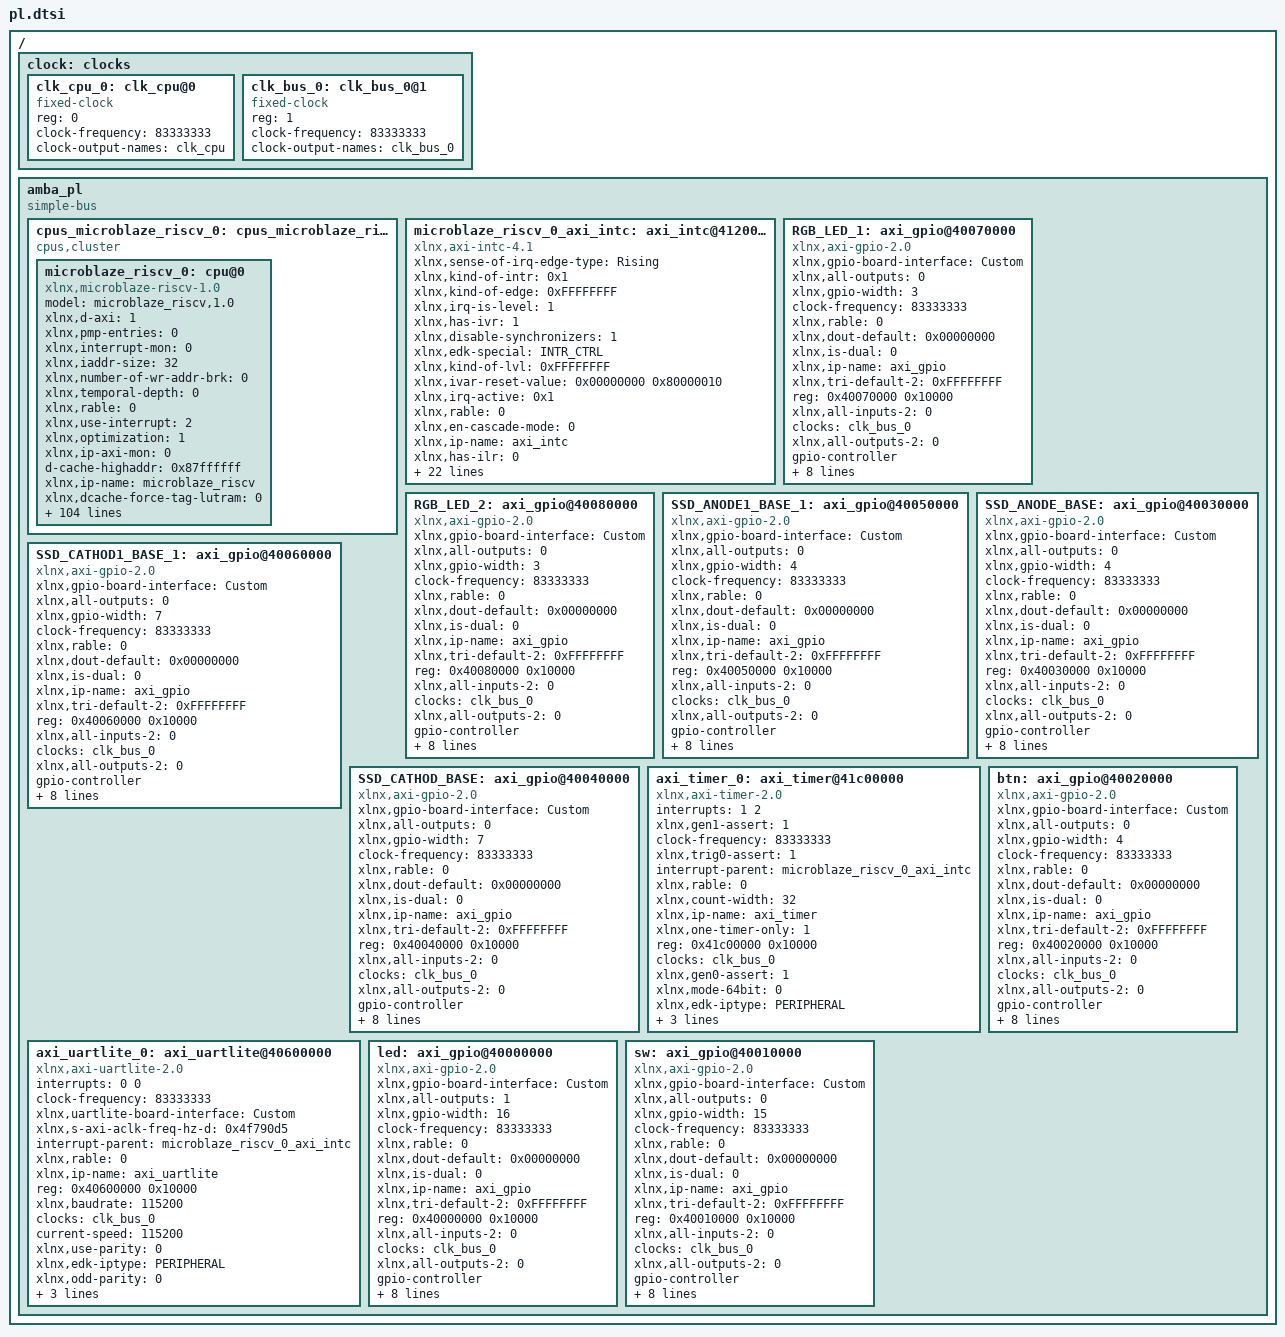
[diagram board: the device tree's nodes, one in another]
/ {
	clock: clocks {
		#address-cells = <1>;
		#size-cells = <0>;
		clk_cpu_0: clk_cpu@0 {
			compatible = "fixed-clock";
			reg = <0>;
			clock-frequency = <83333333>;
			clock-output-names = "clk_cpu";
			#clock-cells = <0>;
		};
		clk_bus_0: clk_bus_0@1 {
			compatible = "fixed-clock";
			reg = <1>;
			clock-frequency = <83333333>;
			clock-output-names = "clk_bus_0";
			#clock-cells = <0>;
		};
	};
	amba_pl: amba_pl {
		ranges;
		compatible = "simple-bus";
		#address-cells = <1>;
		#size-cells = <1>;
		cpus_microblaze_riscv_0: cpus_microblaze_riscv@0 {
			#cpu-mask-cells = <1>;
			compatible = "cpus,cluster";
			#address-cells = <1>;
			#size-cells = <0>;
			microblaze_riscv_0: cpu@0 {
				model = "microblaze_riscv,1.0";
				xlnx,d-axi = <1>;
				xlnx,pmp-entries = <0>;
				xlnx,interrupt-mon = <0>;
				xlnx,iaddr-size = <32>;
				xlnx,number-of-wr-addr-brk = <0>;
				xlnx,temporal-depth = <0>;
				xlnx,rable = <0>;
				xlnx,use-interrupt = <2>;
				xlnx,optimization = <1>;
				xlnx,ip-axi-mon = <0>;
				d-cache-highaddr = <0x87ffffff>;
				xlnx,ip-name = "microblaze_riscv";
				xlnx,dcache-force-tag-lutram = <0>;
				xlnx,pc-width = <27>;
				xlnx,interrupt-is-edge = <0>;
				reg = <0x0>;
				xlnx,async-interrupt = <1>;
				xlnx,use-mmu = <0>;
				xlnx,icache-victims = <0>;
				xlnx,use-bitman-a = <0>;
				xlnx,d-lmb-mon = <0>;
				xlnx,d-lmb-protocol = <0>;
				xlnx,use-bitman-b = <0>;
				xlnx,use-bitman-c = <0>;
				xlnx,dc-axi-mon = <0>;
				xlnx,debug-trace-async-reset = <0>;
				xlnx,trace = <0>;
				xlnx,part = "xc7s50csga324-1";
				xlnx,use-config-reset = <0>;
				xlnx,i-lmb-mon = <0>;
				xlnx,dcache-byte-size = <4096>;
				xlnx,ill-instr-exception = <1>;
				compatible = "xlnx,microblaze-riscv-1.0" , "xlnx,microblaze_riscv";
				xlnx,data-size = <32>;
				xlnx,fault-tolerant = <0>;
				xlnx,use-sleep = <0>;
				xlnx,debug-trace-size = <8192>;
				xlnx,pmp-granularity = <2>;
				xlnx,mmu-privileged-instr = <0>;
				d-cache-line-size = <16>;
				xlnx,d-lmb = <0>;
				xlnx,enable-discrete-ports = <0>;
				clock-frequency = <83333333>;
				xlnx,debug-interface = <0>;
				xlnx,use-ext-brk = <0>;
				xlnx,daddr-size = <32>;
				xlnx,debug-enabled = <1>;
				xlnx,num-sync-ff-dbg-trace-clk = <2>;
				xlnx,i-lmb-protocol = <0>;
				xlnx,fsl-exception = <0>;
				xlnx,use-extended-fsl-instr = <0>;
				xlnx,dp-axi-mon = <0>;
				xlnx,impid = <0x00000000 0x00000001>;
				xlnx,branch-target-cache-size = <0>;
				xlnx,dcache-use-writeback = <0>;
				xlnx,use-bitman-s = <0>;
				bus-handle = <&amba_pl>;
				xlnx,icache-line-len = <4>;
				xlnx,base-vectors = <0x00000000 0x80000000>;
				xlnx,ecc-use-ce-exception = <0>;
				xlnx,use-dcache = <1>;
				xlnx,use-barrel = <1>;
				xlnx,edk-special = "microblaze_riscv";
				xlnx,use-muldiv = <2>;
				xlnx,addr-size = <32>;
				xlnx,debug-external-trace = <0>;
				xlnx,piaddr-size = <32>;
				xlnx,misaligned-exceptions = <1>;
				xlnx,use-bitman = <0>;
				xlnx,num-sync-ff-clk-debug = <2>;
				xlnx,debug-event-counters = <0>;
				xlnx,use-atomic = <0>;
				xlnx,i-axi = <1>;
				xlnx,icache-streams = <0>;
				xlnx,g-template-list = <1>;
				xlnx,dcache-line-len = <4>;
				xlnx,num-sync-ff-clk = <2>;
				xlnx,num-sync-ff-dbg-clk = <1>;
				xlnx,interconnect = <2>;
				xlnx,hartid = <0x00000000 0x00000000>;
				xlnx,debug-latency-counters = <0>;
				xlnx,edk-iptype = "PROCESSOR";
				xlnx,use-fpu = <0>;
				xlnx,icache-byte-size = <8192>;
				xlnx,edge-is-positive = <1>;
				xlnx,use-icache = <0>;
				d-cache-size = <4096>;
				xlnx,async-wakeup = <3>;
				xlnx,use-non-secure = <0>;
				xlnx,number-of-rd-addr-brk = <0>;
				d-cache-baseaddr = <0x80000000>;
				xlnx,use-compression = <1>;
				xlnx,avoid-primitives = <0>;
				xlnx,use-counters = <1>;
				xlnx,lockstep-slave = <0>;
				xlnx,use-ext-nm-brk = <0>;
				xlnx,pdaddr-size = <32>;
				xlnx,instr-size = <32>;
				interrupt-handle = <&microblaze_riscv_0_axi_intc>;
				xlnx,i-lmb = <0>;
				xlnx,lockstep-select = <0>;
				xlnx,lmb-data-size = <32>;
				xlnx,ic-axi-mon = <0>;
				xlnx,num-sync-ff-clk-irq = <1>;
				xlnx,fsl-links = <0>;
				timebase-frequency = <83333333>;
				xlnx,archid = <0x00000000 0x00000001>;
				xlnx,icache-force-tag-lutram = <0>;
				xlnx,dcache-data-width = <0>;
				xlnx,dcache-victims = <0>;
				xlnx,use-branch-target-cache = <0>;
				xlnx,debug-profile-size = <0>;
				xlnx,lockstep-master = <0>;
				xlnx,freq = <83333333>;
				xlnx,number-of-pc-brk = <1>;
				xlnx,imprecise-exceptions = <0>;
				xlnx,icache-data-width = <0>;
				xlnx,debug-counter-width = <64>;
			};
		};
		microblaze_riscv_0_axi_intc: axi_intc@41200000 {
			#interrupt-cells = <2>;
			xlnx,sense-of-irq-edge-type = "Rising";
			xlnx,kind-of-intr = <0x1>;
			xlnx,kind-of-edge = <0xFFFFFFFF>;
			xlnx,irq-is-level = <1>;
			xlnx,has-ivr = <1>;
			compatible = "xlnx,axi-intc-4.1" , "xlnx,xps-intc-1.00.a";
			xlnx,disable-synchronizers = <1>;
			xlnx,edk-special = "INTR_CTRL";
			xlnx,kind-of-lvl = <0xFFFFFFFF>;
			xlnx,ivar-reset-value = <0x00000000 0x80000010>;
			xlnx,irq-active = <0x1>;
			xlnx,rable = <0>;
			xlnx,en-cascade-mode = <0>;
			xlnx,ip-name = "axi_intc";
			xlnx,has-ilr = <0>;
			reg = <0x41200000 0x10000>;
			xlnx,addr-width = <0x20>;
			xlnx,s-axi-aclk-freq-mhz = <0x4f790d5>;
			xlnx,num-sw-intr = <0>;
			xlnx,irq-connection = <0>;
			xlnx,num-intr-inputs = <0x2>;
			xlnx,has-sie = <1>;
			xlnx,has-cie = <1>;
			xlnx,enable-async = <0>;
			xlnx,num-sync-ff = <2>;
			xlnx,mb-clk-not-connected = <1>;
			xlnx,has-ipr = <1>;
			xlnx,edk-iptype = "PERIPHERAL";
			xlnx,sense-of-irq-level-type = "Active_High";
			xlnx,cascade-master = <0>;
			xlnx,processor-clk-freq-mhz = <0x4f790d5>;
			status = "okay";
			xlnx,is-fast = <0x1>;
			xlnx,has-fast = <1>;
			xlnx,ivar-rst-val = <0x0000000080000010>;
			interrupt-controller;
			xlnx,async-intr = <0xFFFFFFFC>;
			xlnx,name = "microblaze_riscv_0_axi_intc";
		};
		RGB_LED_1: axi_gpio@40070000 {
			xlnx,gpio-board-interface = "Custom";
			compatible = "xlnx,axi-gpio-2.0" , "xlnx,xps-gpio-1.00.a";
			xlnx,all-outputs = <0>;
			#gpio-cells = <2>;
			xlnx,gpio-width = <3>;
			clock-frequency = <83333333>;
			xlnx,rable = <0>;
			xlnx,dout-default = <0x00000000>;
			xlnx,is-dual = <0>;
			xlnx,ip-name = "axi_gpio";
			xlnx,tri-default-2 = <0xFFFFFFFF>;
			reg = <0x40070000 0x10000>;
			xlnx,all-inputs-2 = <0>;
			clocks = <&clk_bus_0>;
			xlnx,all-outputs-2 = <0>;
			gpio-controller;
			xlnx,interrupt-present = <0>;
			xlnx,gpio2-board-interface = "Custom";
			xlnx,edk-iptype = "PERIPHERAL";
			xlnx,dout-default-2 = <0x00000000>;
			xlnx,gpio2-width = <32>;
			status = "okay";
			clock-names = "s_axi_aclk";
			xlnx,tri-default = <0xFFFFFFFF>;
			xlnx,name = "RGB_LED_1";
			xlnx,all-inputs = <0>;
		};
		RGB_LED_2: axi_gpio@40080000 {
			xlnx,gpio-board-interface = "Custom";
			compatible = "xlnx,axi-gpio-2.0" , "xlnx,xps-gpio-1.00.a";
			xlnx,all-outputs = <0>;
			#gpio-cells = <2>;
			xlnx,gpio-width = <3>;
			clock-frequency = <83333333>;
			xlnx,rable = <0>;
			xlnx,dout-default = <0x00000000>;
			xlnx,is-dual = <0>;
			xlnx,ip-name = "axi_gpio";
			xlnx,tri-default-2 = <0xFFFFFFFF>;
			reg = <0x40080000 0x10000>;
			xlnx,all-inputs-2 = <0>;
			clocks = <&clk_bus_0>;
			xlnx,all-outputs-2 = <0>;
			gpio-controller;
			xlnx,interrupt-present = <0>;
			xlnx,gpio2-board-interface = "Custom";
			xlnx,edk-iptype = "PERIPHERAL";
			xlnx,dout-default-2 = <0x00000000>;
			xlnx,gpio2-width = <32>;
			status = "okay";
			clock-names = "s_axi_aclk";
			xlnx,tri-default = <0xFFFFFFFF>;
			xlnx,name = "RGB_LED_2";
			xlnx,all-inputs = <0>;
		};
		SSD_ANODE1_BASE_1: axi_gpio@40050000 {
			xlnx,gpio-board-interface = "Custom";
			compatible = "xlnx,axi-gpio-2.0" , "xlnx,xps-gpio-1.00.a";
			xlnx,all-outputs = <0>;
			#gpio-cells = <2>;
			xlnx,gpio-width = <4>;
			clock-frequency = <83333333>;
			xlnx,rable = <0>;
			xlnx,dout-default = <0x00000000>;
			xlnx,is-dual = <0>;
			xlnx,ip-name = "axi_gpio";
			xlnx,tri-default-2 = <0xFFFFFFFF>;
			reg = <0x40050000 0x10000>;
			xlnx,all-inputs-2 = <0>;
			clocks = <&clk_bus_0>;
			xlnx,all-outputs-2 = <0>;
			gpio-controller;
			xlnx,interrupt-present = <0>;
			xlnx,gpio2-board-interface = "Custom";
			xlnx,edk-iptype = "PERIPHERAL";
			xlnx,dout-default-2 = <0x00000000>;
			xlnx,gpio2-width = <32>;
			status = "okay";
			clock-names = "s_axi_aclk";
			xlnx,tri-default = <0xFFFFFFFF>;
			xlnx,name = "SSD_ANODE1_BASE_1";
			xlnx,all-inputs = <0>;
		};
		SSD_ANODE_BASE: axi_gpio@40030000 {
			xlnx,gpio-board-interface = "Custom";
			compatible = "xlnx,axi-gpio-2.0" , "xlnx,xps-gpio-1.00.a";
			xlnx,all-outputs = <0>;
			#gpio-cells = <2>;
			xlnx,gpio-width = <4>;
			clock-frequency = <83333333>;
			xlnx,rable = <0>;
			xlnx,dout-default = <0x00000000>;
			xlnx,is-dual = <0>;
			xlnx,ip-name = "axi_gpio";
			xlnx,tri-default-2 = <0xFFFFFFFF>;
			reg = <0x40030000 0x10000>;
			xlnx,all-inputs-2 = <0>;
			clocks = <&clk_bus_0>;
			xlnx,all-outputs-2 = <0>;
			gpio-controller;
			xlnx,interrupt-present = <0>;
			xlnx,gpio2-board-interface = "Custom";
			xlnx,edk-iptype = "PERIPHERAL";
			xlnx,dout-default-2 = <0x00000000>;
			xlnx,gpio2-width = <32>;
			status = "okay";
			clock-names = "s_axi_aclk";
			xlnx,tri-default = <0xFFFFFFFF>;
			xlnx,name = "SSD_ANODE_BASE";
			xlnx,all-inputs = <0>;
		};
		SSD_CATHOD1_BASE_1: axi_gpio@40060000 {
			xlnx,gpio-board-interface = "Custom";
			compatible = "xlnx,axi-gpio-2.0" , "xlnx,xps-gpio-1.00.a";
			xlnx,all-outputs = <0>;
			#gpio-cells = <2>;
			xlnx,gpio-width = <7>;
			clock-frequency = <83333333>;
			xlnx,rable = <0>;
			xlnx,dout-default = <0x00000000>;
			xlnx,is-dual = <0>;
			xlnx,ip-name = "axi_gpio";
			xlnx,tri-default-2 = <0xFFFFFFFF>;
			reg = <0x40060000 0x10000>;
			xlnx,all-inputs-2 = <0>;
			clocks = <&clk_bus_0>;
			xlnx,all-outputs-2 = <0>;
			gpio-controller;
			xlnx,interrupt-present = <0>;
			xlnx,gpio2-board-interface = "Custom";
			xlnx,edk-iptype = "PERIPHERAL";
			xlnx,dout-default-2 = <0x00000000>;
			xlnx,gpio2-width = <32>;
			status = "okay";
			clock-names = "s_axi_aclk";
			xlnx,tri-default = <0xFFFFFFFF>;
			xlnx,name = "SSD_CATHOD1_BASE_1";
			xlnx,all-inputs = <0>;
		};
		SSD_CATHOD_BASE: axi_gpio@40040000 {
			xlnx,gpio-board-interface = "Custom";
			compatible = "xlnx,axi-gpio-2.0" , "xlnx,xps-gpio-1.00.a";
			xlnx,all-outputs = <0>;
			#gpio-cells = <2>;
			xlnx,gpio-width = <7>;
			clock-frequency = <83333333>;
			xlnx,rable = <0>;
			xlnx,dout-default = <0x00000000>;
			xlnx,is-dual = <0>;
			xlnx,ip-name = "axi_gpio";
			xlnx,tri-default-2 = <0xFFFFFFFF>;
			reg = <0x40040000 0x10000>;
			xlnx,all-inputs-2 = <0>;
			clocks = <&clk_bus_0>;
			xlnx,all-outputs-2 = <0>;
			gpio-controller;
			xlnx,interrupt-present = <0>;
			xlnx,gpio2-board-interface = "Custom";
			xlnx,edk-iptype = "PERIPHERAL";
			xlnx,dout-default-2 = <0x00000000>;
			xlnx,gpio2-width = <32>;
			status = "okay";
			clock-names = "s_axi_aclk";
			xlnx,tri-default = <0xFFFFFFFF>;
			xlnx,name = "SSD_CATHOD_BASE";
			xlnx,all-inputs = <0>;
		};
		axi_timer_0: axi_timer@41c00000 {
			interrupts = < 1 2 >;
			compatible = "xlnx,axi-timer-2.0" , "xlnx,xps-timer-1.00.a";
			xlnx,gen1-assert = <1>;
			clock-frequency = <83333333>;
			xlnx,trig0-assert = <1>;
			interrupt-parent = <&microblaze_riscv_0_axi_intc>;
			xlnx,rable = <0>;
			xlnx,count-width = <32>;
			xlnx,ip-name = "axi_timer";
			xlnx,one-timer-only = <1>;
			reg = <0x41c00000 0x10000>;
			clocks = <&clk_bus_0>;
			xlnx,gen0-assert = <1>;
			xlnx,mode-64bit = <0>;
			xlnx,edk-iptype = "PERIPHERAL";
			xlnx,trig1-assert = <1>;
			status = "okay";
			xlnx,enable-timer2 = <0>;
			interrupt-names = "interrupt";
			xlnx,name = "axi_timer_0";
		};
		axi_uartlite_0: axi_uartlite@40600000 {
			interrupts = < 0 0 >;
			compatible = "xlnx,axi-uartlite-2.0" , "xlnx,xps-uartlite-1.00.a";
			clock-frequency = <83333333>;
			xlnx,uartlite-board-interface = "Custom";
			xlnx,s-axi-aclk-freq-hz-d = <0x4f790d5>;
			interrupt-parent = <&microblaze_riscv_0_axi_intc>;
			xlnx,rable = <0>;
			xlnx,ip-name = "axi_uartlite";
			reg = <0x40600000 0x10000>;
			xlnx,baudrate = <115200>;
			clocks = <&clk_bus_0>;
			current-speed = <115200>;
			xlnx,use-parity = <0>;
			xlnx,edk-iptype = "PERIPHERAL";
			xlnx,odd-parity = <0>;
			status = "okay";
			interrupt-names = "interrupt";
			xlnx,name = "axi_uartlite_0";
			xlnx,data-bits = <8>;
			xlnx,parity = "No_Parity";
		};
		btn: axi_gpio@40020000 {
			xlnx,gpio-board-interface = "Custom";
			compatible = "xlnx,axi-gpio-2.0" , "xlnx,xps-gpio-1.00.a";
			xlnx,all-outputs = <0>;
			#gpio-cells = <2>;
			xlnx,gpio-width = <4>;
			clock-frequency = <83333333>;
			xlnx,rable = <0>;
			xlnx,dout-default = <0x00000000>;
			xlnx,is-dual = <0>;
			xlnx,ip-name = "axi_gpio";
			xlnx,tri-default-2 = <0xFFFFFFFF>;
			reg = <0x40020000 0x10000>;
			xlnx,all-inputs-2 = <0>;
			clocks = <&clk_bus_0>;
			xlnx,all-outputs-2 = <0>;
			gpio-controller;
			xlnx,interrupt-present = <0>;
			xlnx,gpio2-board-interface = "Custom";
			xlnx,edk-iptype = "PERIPHERAL";
			xlnx,dout-default-2 = <0x00000000>;
			xlnx,gpio2-width = <32>;
			status = "okay";
			clock-names = "s_axi_aclk";
			xlnx,tri-default = <0xFFFFFFFF>;
			xlnx,name = "btn";
			xlnx,all-inputs = <1>;
		};
		led: axi_gpio@40000000 {
			xlnx,gpio-board-interface = "Custom";
			compatible = "xlnx,axi-gpio-2.0" , "xlnx,xps-gpio-1.00.a";
			xlnx,all-outputs = <1>;
			#gpio-cells = <2>;
			xlnx,gpio-width = <16>;
			clock-frequency = <83333333>;
			xlnx,rable = <0>;
			xlnx,dout-default = <0x00000000>;
			xlnx,is-dual = <0>;
			xlnx,ip-name = "axi_gpio";
			xlnx,tri-default-2 = <0xFFFFFFFF>;
			reg = <0x40000000 0x10000>;
			xlnx,all-inputs-2 = <0>;
			clocks = <&clk_bus_0>;
			xlnx,all-outputs-2 = <0>;
			gpio-controller;
			xlnx,interrupt-present = <0>;
			xlnx,gpio2-board-interface = "Custom";
			xlnx,edk-iptype = "PERIPHERAL";
			xlnx,dout-default-2 = <0x00000000>;
			xlnx,gpio2-width = <32>;
			status = "okay";
			clock-names = "s_axi_aclk";
			xlnx,tri-default = <0xFFFFFFFF>;
			xlnx,name = "led";
			xlnx,all-inputs = <0>;
		};
		sw: axi_gpio@40010000 {
			xlnx,gpio-board-interface = "Custom";
			compatible = "xlnx,axi-gpio-2.0" , "xlnx,xps-gpio-1.00.a";
			xlnx,all-outputs = <0>;
			#gpio-cells = <2>;
			xlnx,gpio-width = <15>;
			clock-frequency = <83333333>;
			xlnx,rable = <0>;
			xlnx,dout-default = <0x00000000>;
			xlnx,is-dual = <0>;
			xlnx,ip-name = "axi_gpio";
			xlnx,tri-default-2 = <0xFFFFFFFF>;
			reg = <0x40010000 0x10000>;
			xlnx,all-inputs-2 = <0>;
			clocks = <&clk_bus_0>;
			xlnx,all-outputs-2 = <0>;
			gpio-controller;
			xlnx,interrupt-present = <0>;
			xlnx,gpio2-board-interface = "Custom";
			xlnx,edk-iptype = "PERIPHERAL";
			xlnx,dout-default-2 = <0x00000000>;
			xlnx,gpio2-width = <32>;
			status = "okay";
			clock-names = "s_axi_aclk";
			xlnx,tri-default = <0xFFFFFFFF>;
			xlnx,name = "sw";
			xlnx,all-inputs = <1>;
		};
	};
};
